# PIC32MX270F256D device description
Architecture: MIPS; Family: PIC32MX; Series: PIC32MX
Registers are 32-bit, read-write, no defined reset value unless marked. A register's access mark holds for its fields unless they carry their own. Offsets are from the block's base; [hi:lo] are bit positions; {n}, {i} and the like mark numbered series; 'fields as' and 'values as' point back to an identical list.

## FUSECONFIG
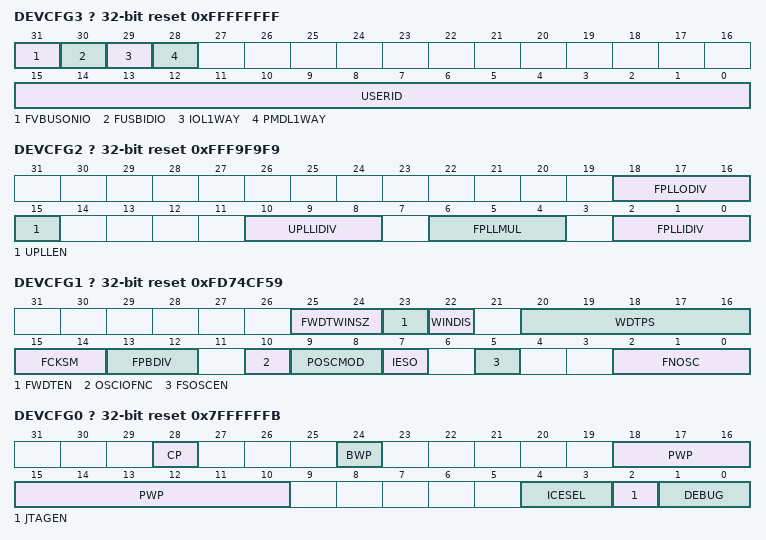
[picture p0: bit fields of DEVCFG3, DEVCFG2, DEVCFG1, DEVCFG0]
? DEVCFG3 size not given access not given reset 0xFFFFFFFF — Device Configuration Word 3
  [31] FVBUSONIO — USB VBUS_ON Selection bit
    0=OFF (VBUSON pin is controlled by the port function); 1=ON (VBUSON pin is controlled by the USB module)
  [30] FUSBIDIO — USB USBID Selection bit
    0=OFF (USBID pin is controlled by the port function); 1=ON (USBID pin is controlled by the USB module)
  [29] IOL1WAY — Peripheral Pin Select Configuration bit
    1=ON (Allow only one reconfiguration); 0=OFF (Allow multiple reconfigurations)
  [28] PMDL1WAY — Peripheral Module Disable Configuration bit
    values as IOL1WAY
  [15:0] USERID
    ?=User ID
? DEVCFG2 size not given access not given reset 0xFFF9F9F9 — Device Configuration Word 2
  [18:16] FPLLODIV — Default PLL Output Divisor bits
    0=DIV_1 (PLL Divide by 1); 1=DIV_2 (PLL Divide by 2); 2=DIV_4 (PLL Divide by 4); 3=DIV_8 (PLL Divide by 8); 4=DIV_16 (PLL Divide by 16); 5=DIV_32 (PLL Divide by 32); 6=DIV_64 (PLL Divide by 64); 7=DIV_256 (PLL Divide by 256)
  [15] UPLLEN — USB PLL Enable bit
    0=ON (Enable USB PLL); 1=OFF (Disable and bypass USB PLL)
  [10:8] UPLLIDIV — USB PLL Input Divider bits
    {v}=DIV_{v+1} ({v+1}x Divider) (v=0..5); 6=DIV_10 (10x Divider); 7=DIV_12 (12x Divider)
  [6:4] FPLLMUL — PLL Multiplier bits
    {v}=MUL_{v+15} ({v+15}x Multiplier) (v=0..6); 7=MUL_24 (24x Multiplier)
  [2:0] FPLLIDIV — PLL Input Divider bits
    values as UPLLIDIV
? DEVCFG1 size not given access not given reset 0xFD74CF59 — Device Configuration Word 1
  [25:24] FWDTWINSZ — Watchdog Timer Window Size bits
    0=WINSZ_75 (Window Size is 75%); 1=WINSZ_50 (Window Size is 50%); 2=WINSZ_37 (Window Size is 37.5%); 3=WINSZ_25 (Window Size is 25%)
  [23] FWDTEN — Watchdog Timer Enable bit
    0=OFF (Watchdog Timer is not enabled; it can be enabled in software); 1=ON (Watchdog Timer is enabled and cannot be disabled by software)
  [22] WINDIS — Watchdog Timer Window Enable bit
    0=ON (Watchdog Timer is in Window Mode); 1=OFF (Watchdog Timer is in Non-Window Mode)
  [20:16] WDTPS — Watchdog Timer Postscale Select bits
    0=PS1 (1:1); 1=PS2 (1:2); 2=PS4 (1:4); 3=PS8 (1:8); 4=PS16 (1:16); 5=PS32 (1:32); 6=PS64 (1:64); 7=PS128 (1:128); 8=PS256 (1:256); 9=PS512 (1:512); 10=PS1024 (1:1024); 11=PS2048 (1:2048); 12=PS4096 (1:4096); 13=PS8192 (1:8192); 14=PS16384 (1:16384); 15=PS32768 (1:32768); 16=PS65536 (1:65536); 17=PS131072 (1:131072); 18=PS262144 (1:262144); 19=PS524288 (1:524288); 20=PS1048576 (1:1048576)
  [15:14] FCKSM — Clock Switching and Monitor Selection Configuration bits
    0=CSECME (Clock Switch Enable, FSCM Enabled); 1=CSECMD (Clock Switch Enable, FSCM Disabled); 3=CSDCMD (Clock Switch Disable, FSCM Disabled)
  [13:12] FPBDIV — Peripheral Bus Clock Divisor Default Value bits
    0=DIV_1 (Pb_Clk is Sys_Clk/1); 1=DIV_2 (Pb_Clk is Sys_Clk/2); 2=DIV_4 (Pb_Clk is Sys_Clk/4); 3=DIV_8 (Pb_Clk is Sys_Clk/8)
  [10] OSCIOFNC — CLKO Enable Configuration bit
    1=OFF (CLKO output disabled); 0=ON (CLKO output signal active on the OSCO pin)
  [9:8] POSCMOD — Primary Oscillator Configuration bits
    0=EC (External clock mode); 1=XT (XT osc mode); 2=HS (HS osc mode); 3=OFF (Primary osc disabled)
  [7] IESO — Internal External Switchover bit
    0=OFF (Internal External Switchover mode is disabled (Two-Speed Start-up is disabled)); 1=ON (Internal External Switchover mode is enabled (Two-Speed Start-up is enabled))
  [5] FSOSCEN — Secondary Oscillator Enable bit
    0=OFF (Disable Secondary Oscillator); 1=ON (Enable Secondary Oscillator)
  [2:0] FNOSC — Oscillator Selection bits
    0=FRC (Fast RC Osc (FRC)); 1=FRCPLL (Fast RC Osc with PLL); 2=PRI (Primary Osc (XT,HS,EC)); 3=PRIPLL (Primary Osc w/PLL (XT+,HS+,EC+PLL)); 4=SOSC (Low Power Secondary Osc (SOSC)); 5=LPRC (Low Power RC Osc (LPRC)); 6=FRCDIV16 (Fast RC Osc w/Div-by-16 (FRC/16)); 7=FRCDIV (Fast RC Osc w/Div-by-N (FRCDIV))
? DEVCFG0 size not given access not given reset 0x7FFFFFFB — Device Configuration Word 0
  [28] CP — Code-Protect bit
    0=ON (Protection Enabled); 1=OFF (Protection Disabled)
  [24] BWP — Boot Flash Write-Protect bit
    0=ON (Boot Flash is not writable); 1=OFF (Boot Flash is writable)
  [18:10] PWP — Program Flash Write-Protect bits
    0x1ff=OFF (Disable); 0x1fe=PWP1K (First 1K); 0x1fd=PWP2K (First 2K); 0x1fc=PWP3K (First 3K); 0x1fb=PWP4K (First 4K); 0x1fa=PWP5K (First 5K); 0x1f9=PWP6K (First 6K); 0x1f8=PWP7K (First 7K); 0x1f7=PWP8K (First 8K); 0x1f6=PWP9K (First 9K); 0x1f5=PWP10K (First 10K); 0x1f4=PWP11K (First 11K); 0x1f3=PWP12K (First 12K); 0x1f2=PWP13K (First 13K); 0x1f1=PWP14K (First 14K); 0x1f0=PWP15K (First 15K); 0x1ef=PWP16K (First 16K); 0x1ee=PWP17K (First 17K); 0x1ed=PWP18K (First 18K); 0x1ec=PWP19K (First 19K); 0x1eb=PWP20K (First 20K); 0x1ea=PWP21K (First 21K); 0x1e9=PWP22K (First 22K); 0x1e8=PWP23K (First 23K); 0x1e7=PWP24K (First 24K); 0x1e6=PWP25K (First 25K); 0x1e5=PWP26K (First 26K); 0x1e4=PWP27K (First 27K); 0x1e3=PWP28K (First 28K); 0x1e2=PWP29K (First 29K); 0x1e1=PWP30K (First 30K); 0x1e0=PWP31K (First 31K); 0x1df=PWP32K (First 32K); 0x1de=PWP33K (First 33K); 0x1dd=PWP34K (First 34K); 0x1dc=PWP35K (First 35K); 0x1db=PWP36K (First 36K); 0x1da=PWP37K (First 37K); 0x1d9=PWP38K (First 38K); 0x1d8=PWP39K (First 39K); 0x1d7=PWP40K (First 40K); 0x1d6=PWP41K (First 41K); 0x1d5=PWP42K (First 42K); 0x1d4=PWP43K (First 43K); 0x1d3=PWP44K (First 44K); 0x1d2=PWP45K (First 45K); 0x1d1=PWP46K (First 46K); 0x1d0=PWP47K (First 47K); 0x1cf=PWP48K (First 48K); 0x1ce=PWP49K (First 49K); 0x1cd=PWP50K (First 50K); 0x1cc=PWP51K (First 51K); 0x1cb=PWP52K (First 52K); 0x1ca=PWP53K (First 53K); 0x1c9=PWP54K (First 54K); 0x1c8=PWP55K (First 55K); 0x1c7=PWP56K (First 56K); 0x1c6=PWP57K (First 57K); 0x1c5=PWP58K (First 58K); 0x1c4=PWP59K (First 59K); 0x1c3=PWP60K (First 60K); 0x1c2=PWP61K (First 61K); 0x1c1=PWP62K (First 62K); 0x1c0=PWP63K (First 63K); 0x1bf=PWP64K (First 64K); 0x1be=PWP65K (First 65K); 0x1bd=PWP66K (First 66K); 0x1bc=PWP67K (First 67K); 0x1bb=PWP68K (First 68K); 0x1ba=PWP69K (First 69K); 0x1b9=PWP70K (First 70K); 0x1b8=PWP71K (First 71K); 0x1b7=PWP72K (First 72K); 0x1b6=PWP73K (First 73K); 0x1b5=PWP74K (First 74K); 0x1b4=PWP75K (First 75K); 0x1b3=PWP76K (First 76K); 0x1b2=PWP77K (First 77K); 0x1b1=PWP78K (First 78K); 0x1b0=PWP79K (First 79K); 0x1af=PWP80K (First 80K); 0x1ae=PWP81K (First 81K); 0x1ad=PWP82K (First 82K); 0x1ac=PWP83K (First 83K); 0x1ab=PWP84K (First 84K); 0x1aa=PWP85K (First 85K); 0x1a9=PWP86K (First 86K); 0x1a8=PWP87K (First 87K); 0x1a7=PWP88K (First 88K); 0x1a6=PWP89K (First 89K); 0x1a5=PWP90K (First 90K); 0x1a4=PWP91K (First 91K); 0x1a3=PWP92K (First 92K); 0x1a2=PWP93K (First 93K); 0x1a1=PWP94K (First 94K); 0x1a0=PWP95K (First 95K); 0x19f=PWP96K (First 96K); 0x19e=PWP97K (First 97K); 0x19d=PWP98K (First 98K); 0x19c=PWP99K (First 99K); 0x19b=PWP100K (First 100K); 0x19a=PWP101K (First 101K); 0x199=PWP102K (First 102K); 0x198=PWP103K (First 103K); 0x197=PWP104K (First 104K); 0x196=PWP105K (First 105K); 0x195=PWP106K (First 106K); 0x194=PWP107K (First 107K); 0x193=PWP108K (First 108K); 0x192=PWP109K (First 109K); 0x191=PWP110K (First 110K); 0x190=PWP111K (First 111K); 0x18f=PWP112K (First 112K); 0x18e=PWP113K (First 113K); 0x18d=PWP114K (First 114K); 0x18c=PWP115K (First 115K); 0x18b=PWP116K (First 116K); 0x18a=PWP117K (First 117K); 0x189=PWP118K (First 118K); 0x188=PWP119K (First 119K); 0x187=PWP120K (First 120K); 0x186=PWP121K (First 121K); 0x185=PWP122K (First 122K); 0x184=PWP123K (First 123K); 0x183=PWP124K (First 124K); 0x182=PWP125K (First 125K); 0x181=PWP126K (First 126K); 0x180=PWP127K (First 127K); 0x17f=PWP128K (First 128K); 0x17e=PWP129K (First 129K); 0x17d=PWP130K (First 130K); 0x17c=PWP131K (First 131K); 0x17b=PWP132K (First 132K); 0x17a=PWP133K (First 133K); 0x179=PWP134K (First 134K); 0x178=PWP135K (First 135K); 0x177=PWP136K (First 136K); 0x176=PWP137K (First 137K); 0x175=PWP138K (First 138K); 0x174=PWP139K (First 139K); 0x173=PWP140K (First 140K); 0x172=PWP141K (First 141K); 0x171=PWP142K (First 142K); 0x170=PWP143K (First 143K); 0x16f=PWP144K (First 144K); 0x16e=PWP145K (First 145K); 0x16d=PWP146K (First 146K); 0x16c=PWP147K (First 147K); 0x16b=PWP148K (First 148K); 0x16a=PWP149K (First 149K); 0x169=PWP150K (First 150K); 0x168=PWP151K (First 151K); 0x167=PWP152K (First 152K); 0x166=PWP153K (First 153K); 0x165=PWP154K (First 154K); 0x164=PWP155K (First 155K); 0x163=PWP156K (First 156K); 0x162=PWP157K (First 157K); 0x161=PWP158K (First 158K); 0x160=PWP159K (First 159K); 0x15f=PWP160K (First 160K); 0x15e=PWP161K (First 161K); 0x15d=PWP162K (First 162K); 0x15c=PWP163K (First 163K); 0x15b=PWP164K (First 164K); 0x15a=PWP165K (First 165K); 0x159=PWP166K (First 166K); 0x158=PWP167K (First 167K); 0x157=PWP168K (First 168K); 0x156=PWP169K (First 169K); 0x155=PWP170K (First 170K); 0x154=PWP171K (First 171K); 0x153=PWP172K (First 172K); 0x152=PWP173K (First 173K); 0x151=PWP174K (First 174K); 0x150=PWP175K (First 175K); 0x14f=PWP176K (First 176K); 0x14e=PWP177K (First 177K); 0x14d=PWP178K (First 178K); 0x14c=PWP179K (First 179K); 0x14b=PWP180K (First 180K); 0x14a=PWP181K (First 181K); 0x149=PWP182K (First 182K); 0x148=PWP183K (First 183K); 0x147=PWP184K (First 184K); 0x146=PWP185K (First 185K); 0x145=PWP186K (First 186K); 0x144=PWP187K (First 187K); 0x143=PWP188K (First 188K); 0x142=PWP189K (First 189K); 0x141=PWP190K (First 190K); 0x140=PWP191K (First 191K); 0x13f=PWP192K (First 192K); 0x13e=PWP193K (First 193K); 0x13d=PWP194K (First 194K); 0x13c=PWP195K (First 195K); 0x13b=PWP196K (First 196K); 0x13a=PWP197K (First 197K); 0x139=PWP198K (First 198K); 0x138=PWP199K (First 199K); 0x137=PWP200K (First 200K); 0x136=PWP201K (First 201K); 0x135=PWP202K (First 202K); 0x134=PWP203K (First 203K); 0x133=PWP204K (First 204K); 0x132=PWP205K (First 205K); 0x131=PWP206K (First 206K); 0x130=PWP207K (First 207K); 0x12f=PWP208K (First 208K); 0x12e=PWP209K (First 209K); 0x12d=PWP210K (First 210K); 0x12c=PWP211K (First 211K); 0x12b=PWP212K (First 212K); 0x12a=PWP213K (First 213K); 0x129=PWP214K (First 214K); 0x128=PWP215K (First 215K); 0x127=PWP216K (First 216K); 0x126=PWP217K (First 217K); 0x125=PWP218K (First 218K); 0x124=PWP219K (First 219K); 0x123=PWP220K (First 220K); 0x122=PWP221K (First 221K); 0x121=PWP222K (First 222K); 0x120=PWP223K (First 223K); 0x11f=PWP224K (First 224K); 0x11e=PWP225K (First 225K); 0x11d=PWP226K (First 226K); 0x11c=PWP227K (First 227K); 0x11b=PWP228K (First 228K); 0x11a=PWP229K (First 229K); 0x119=PWP230K (First 230K); 0x118=PWP231K (First 231K); 0x117=PWP232K (First 232K); 0x116=PWP233K (First 233K); 0x115=PWP234K (First 234K); 0x114=PWP235K (First 235K); 0x113=PWP236K (First 236K); 0x112=PWP237K (First 237K); 0x111=PWP238K (First 238K); 0x110=PWP239K (First 239K); 0x10f=PWP240K (First 240K); 0x10e=PWP241K (First 241K); 0x10d=PWP242K (First 242K); 0x10c=PWP243K (First 243K); 0x10b=PWP244K (First 244K); 0x10a=PWP245K (First 245K); 0x109=PWP246K (First 246K); 0x108=PWP247K (First 247K); 0x107=PWP248K (First 248K); 0x106=PWP249K (First 249K); 0x105=PWP250K (First 250K); 0x104=PWP251K (First 251K); 0x103=PWP252K (First 252K); 0x102=PWP253K (First 253K); 0x101=PWP254K (First 254K); 0x100=PWP255K (First 255K); 255=PWP256K (First 256K)
  [4:3] ICESEL — In-Circuit Emulator/Debugger Communication Channel Select bits
    3=ICS_PGx1 (Communicate on PGEC1/PGED1); 2=ICS_PGx2 (Communicate on PGEC2/PGED2); 1=ICS_PGx3 (Communicate on PGEC3/PGED3); 0=ICS_PGx4 (Communicate on PGEC4/PGED4)
  [2] JTAGEN — JTAG Enable bit
    1=ON (JTAG Port Enabled); 0=OFF (JTAG Disabled)
  [1:0] DEBUG — Background Debugger Enable bits (forced to 11 if code-protect is enabled)
    0=ON (Debugger is Enabled); 3=OFF (Debugger is Disabled)

## Notices in the file
Copyright (c) 2019 Microchip Technology Inc.
SPDX-License-Identifier: Apache-2.0
Licensed under the Apache License, Version 2.0 (the "License");
you may not use this file except in compliance with the License.
You may obtain a copy of the License at
http://www.apache.org/licenses/LICENSE-2.0
Unless required by applicable law or agreed to in writing, software
distributed under the License is distributed on an "AS IS" BASIS,
WITHOUT WARRANTIES OR CONDITIONS OF ANY KIND, either express or implied.
See the License for the specific language governing permissions and
limitations under the License.
